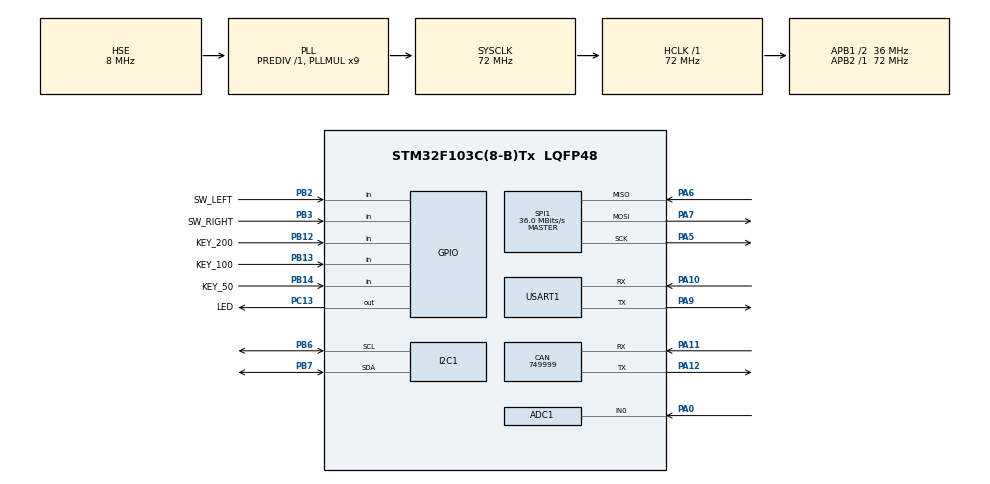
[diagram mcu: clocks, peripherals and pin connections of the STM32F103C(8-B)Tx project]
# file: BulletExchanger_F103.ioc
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ADC1.Channel-2\#ChannelRegularConversion=ADC_CHANNEL_0
ADC1.NbrOfConversionFlag=1
ADC1.Rank-2\#ChannelRegularConversion=1
ADC1.SamplingTime-2\#ChannelRegularConversion=ADC_SAMPLETIME_1CYCLE_5
ADC1.master=1
CAN.CalculateBaudRate=749999
CAN.CalculateTimeBit=1333
CAN.CalculateTimeQuantum=444.44444444444446
Dma.Request0=USART1_TX
Dma.Request1=USART1_RX
Dma.USART1_RX.1.Direction=DMA_PERIPH_TO_MEMORY
Dma.USART1_RX.1.Instance=DMA1_Channel5
Dma.USART1_RX.1.MemDataAlignment=DMA_MDATAALIGN_BYTE
Dma.USART1_RX.1.MemInc=DMA_MINC_ENABLE
Dma.USART1_RX.1.Mode=DMA_NORMAL
Dma.USART1_RX.1.PeriphDataAlignment=DMA_PDATAALIGN_BYTE
Dma.USART1_RX.1.PeriphInc=DMA_PINC_DISABLE
Dma.USART1_RX.1.Priority=DMA_PRIORITY_LOW
Dma.USART1_TX.0.Direction=DMA_MEMORY_TO_PERIPH
Dma.USART1_TX.0.Instance=DMA1_Channel4
Dma.USART1_TX.0.MemDataAlignment=DMA_MDATAALIGN_BYTE
Dma.USART1_TX.0.MemInc=DMA_MINC_ENABLE
Dma.USART1_TX.0.Mode=DMA_NORMAL
Dma.USART1_TX.0.PeriphDataAlignment=DMA_PDATAALIGN_BYTE
Dma.USART1_TX.0.PeriphInc=DMA_PINC_DISABLE
Dma.USART1_TX.0.Priority=DMA_PRIORITY_LOW
FREERTOS.Tasks01=defaultTask,24,256,StartDefaultTask,Default,NULL,Dynamic,NULL,NULL
FREERTOS.configTOTAL_HEAP_SIZE=10240
Mcu.Family=STM32F1
Mcu.Name=STM32F103C(8-B)Tx
Mcu.Package=LQFP48
NVIC.DMA1_Channel4_IRQn=true\:5\:0\:false\:false\:true\:true\:false\:true\:true
NVIC.DMA1_Channel5_IRQn=true\:5\:0\:false\:false\:true\:true\:false\:true\:true
NVIC.PriorityGroup=NVIC_PRIORITYGROUP_4
NVIC.USART1_IRQn=true\:5\:0\:false\:false\:true\:true\:false\:true\:true
PA0-WKUP.Signal=ADCx_IN0
PA10.Mode=Asynchronous
PA10.Signal=USART1_RX
PA11.Mode=CAN_Activate
PA11.Signal=CAN_RX
PA12.Mode=CAN_Activate
PA12.Signal=CAN_TX
PA13.Mode=Serial_Wire
PA13.Signal=SYS_JTMS-SWDIO
PA14.Mode=Serial_Wire
PA14.Signal=SYS_JTCK-SWCLK
PA5.Mode=Full_Duplex_Master
PA5.Signal=SPI1_SCK
PA6.Mode=Full_Duplex_Master
PA6.Signal=SPI1_MISO
PA7.Mode=Full_Duplex_Master
PA7.Signal=SPI1_MOSI
PA9.Mode=Asynchronous
PA9.Signal=USART1_TX
PB12.GPIO_Label=KEY_200
PB12.GPIO_PuPd=GPIO_PULLUP
PB12.Signal=GPIO_Input
PB13.GPIO_Label=KEY_100
PB13.GPIO_PuPd=GPIO_PULLUP
PB13.Signal=GPIO_Input
PB14.GPIO_Label=KEY_50
PB14.GPIO_PuPd=GPIO_PULLUP
PB14.Signal=GPIO_Input
PB2.GPIO_Label=SW_LEFT
PB2.GPIO_PuPd=GPIO_PULLUP
PB2.Signal=GPIO_Input
PB3.GPIO_Label=SW_RIGHT
PB3.GPIO_PuPd=GPIO_PULLUP
PB3.Signal=GPIO_Input
PB6.Mode=I2C
PB6.Signal=I2C1_SCL
PB7.Mode=I2C
PB7.Signal=I2C1_SDA
PC13-TAMPER-RTC.GPIO_Label=LED
PC13-TAMPER-RTC.PinState=GPIO_PIN_SET
PC13-TAMPER-RTC.Signal=GPIO_Output
PD0-OSC_IN.Mode=HSE-External-Oscillator
PD0-OSC_IN.Signal=RCC_OSC_IN
PD1-OSC_OUT.Mode=HSE-External-Oscillator
PD1-OSC_OUT.Signal=RCC_OSC_OUT
ProjectManager.HeapSize=0x200
ProjectManager.StackSize=0x400
ProjectManager.TargetToolchain=Makefile
RCC.AHBFreq_Value=72000000
RCC.APB1CLKDivider=RCC_HCLK_DIV2
RCC.APB1Freq_Value=36000000
RCC.APB1TimFreq_Value=72000000
RCC.APB2Freq_Value=72000000
RCC.APB2TimFreq_Value=72000000
RCC.HCLKFreq_Value=72000000
RCC.PLLMUL=RCC_PLL_MUL9
RCC.PLLSourceVirtual=RCC_PLLSOURCE_HSE
RCC.SYSCLKFreq_VALUE=72000000
RCC.SYSCLKSource=RCC_SYSCLKSOURCE_PLLCLK
RCC.USBFreq_Value=72000000
SH.ADCx_IN0.0=ADC1_IN0,IN0
SPI1.BaudRatePrescaler=SPI_BAUDRATEPRESCALER_2
SPI1.CalculateBaudRate=36.0 MBits/s
SPI1.Direction=SPI_DIRECTION_2LINES
SPI1.Mode=SPI_MODE_MASTER
SPI1.VirtualType=VM_MASTER
USART1.VirtualMode=VM_ASYNC
VP_CRC_VS_CRC.Mode=CRC_Activate
VP_FREERTOS_VS_CMSIS_V2.Mode=CMSIS_V2
VP_RTC_VS_RTC_Activate.Mode=RTC_Enabled
VP_RTC_VS_RTC_Calendar.Mode=RTC_Calendar
VP_TIM3_VS_ClockSourceINT.Mode=Internal
board=custom

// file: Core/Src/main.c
/* USER CODE BEGIN Header */
/**
  ******************************************************************************
  * @file           : main.c
  * @brief          : Main program body
  ******************************************************************************
  * @attention
  *
  * Copyright (c) 2026 STMicroelectronics.
  * All rights reserved.
  *
  * This software is licensed under terms that can be found in the LICENSE file
  * in the root directory of this software component.
  * If no LICENSE file comes with this software, it is provided AS-IS.
  *
  ******************************************************************************
  */
/* USER CODE END Header */
#include "main.h"
#include "cmsis_os.h"
#include "adc.h"
#include "can.h"
#include "crc.h"
#include "dma.h"
#include "i2c.h"
#include "rtc.h"
#include "spi.h"
#include "tim.h"
#include "usart.h"
#include "gpio.h"

void SystemClock_Config(void);
void MX_FREERTOS_Init(void);

int main(void)
{

  /* MCU Configuration--------------------------------------------------------*/

  /* Reset of all peripherals, Initializes the Flash interface and the Systick. */
  HAL_Init();

  /* Configure the system clock */
  SystemClock_Config();

  /* Initialize all configured peripherals */
  MX_GPIO_Init();
  MX_DMA_Init();
  MX_USART1_UART_Init();
  MX_ADC1_Init();
  MX_CAN_Init();
  MX_CRC_Init();
  MX_I2C1_Init();
  MX_RTC_Init();
  MX_SPI1_Init();
  MX_TIM3_Init();

  /* Init scheduler */
  osKernelInitialize();  /* Call init function for freertos objects (in cmsis_os2.c) */
  MX_FREERTOS_Init();

  /* Start scheduler */
  osKernelStart();

  /* We should never get here as control is now taken by the scheduler */

  /* Infinite loop */
  while (1)
  {

  }
}

void SystemClock_Config(void)
{
  RCC_OscInitTypeDef RCC_OscInitStruct = {0};
  RCC_ClkInitTypeDef RCC_ClkInitStruct = {0};
  RCC_PeriphCLKInitTypeDef PeriphClkInit = {0};

  /** Initializes the RCC Oscillators according to the specified parameters
  * in the RCC_OscInitTypeDef structure.
  */
  RCC_OscInitStruct.OscillatorType = RCC_OSCILLATORTYPE_LSI|RCC_OSCILLATORTYPE_HSE;
  RCC_OscInitStruct.HSEState = RCC_HSE_ON;
  RCC_OscInitStruct.HSEPredivValue = RCC_HSE_PREDIV_DIV1;
  RCC_OscInitStruct.HSIState = RCC_HSI_ON;
  RCC_OscInitStruct.LSIState = RCC_LSI_ON;
  RCC_OscInitStruct.PLL.PLLState = RCC_PLL_ON;
  RCC_OscInitStruct.PLL.PLLSource = RCC_PLLSOURCE_HSE;
  RCC_OscInitStruct.PLL.PLLMUL = RCC_PLL_MUL9;
  if (HAL_RCC_OscConfig(&RCC_OscInitStruct) != HAL_OK)
  {
    Error_Handler();
  }

  /** Initializes the CPU, AHB and APB buses clocks
  */
  RCC_ClkInitStruct.ClockType = RCC_CLOCKTYPE_HCLK|RCC_CLOCKTYPE_SYSCLK
                              |RCC_CLOCKTYPE_PCLK1|RCC_CLOCKTYPE_PCLK2;
  RCC_ClkInitStruct.SYSCLKSource = RCC_SYSCLKSOURCE_PLLCLK;
  RCC_ClkInitStruct.AHBCLKDivider = RCC_SYSCLK_DIV1;
  RCC_ClkInitStruct.APB1CLKDivider = RCC_HCLK_DIV2;
  RCC_ClkInitStruct.APB2CLKDivider = RCC_HCLK_DIV1;

  if (HAL_RCC_ClockConfig(&RCC_ClkInitStruct, FLASH_LATENCY_2) != HAL_OK)
  {
    Error_Handler();
  }
  PeriphClkInit.PeriphClockSelection = RCC_PERIPHCLK_RTC|RCC_PERIPHCLK_ADC;
  PeriphClkInit.RTCClockSelection = RCC_RTCCLKSOURCE_LSI;
  PeriphClkInit.AdcClockSelection = RCC_ADCPCLK2_DIV2;
  if (HAL_RCCEx_PeriphCLKConfig(&PeriphClkInit) != HAL_OK)
  {
    Error_Handler();
  }
}

void Error_Handler(void)
{
  __disable_irq();
  while (1)
  {
  }
}

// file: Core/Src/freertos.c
/* USER CODE BEGIN Header */
/**
  ******************************************************************************
  * File Name          : freertos.c
  * Description        : Code for freertos applications
  ******************************************************************************
  * @attention
  *
  * Copyright (c) 2026 STMicroelectronics.
  * All rights reserved.
  *
  * This software is licensed under terms that can be found in the LICENSE file
  * in the root directory of this software component.
  * If no LICENSE file comes with this software, it is provided AS-IS.
  *
  ******************************************************************************
  */
/* USER CODE END Header */

#include "FreeRTOS.h"
#include "task.h"
#include "main.h"
#include "cmsis_os.h"

/* Definitions for defaultTask */
osThreadId_t defaultTaskHandle;
const osThreadAttr_t defaultTask_attributes = {
  .name = "defaultTask",
  .stack_size = 256 * 4,
  .priority = (osPriority_t) osPriorityNormal,
};

/* USER CODE BEGIN FunctionPrototypes */
/* Overridden by programs/BulletExchanger in the repository CMake build. */
__weak void RM_RTOS_Init(void) {}
__weak void RM_RTOS_Threads_Init(void) {}
__weak void RM_RTOS_Default_Task(const void *argument) { UNUSED(argument); }

/* USER CODE END FunctionPrototypes */

void StartDefaultTask(void *argument);

void MX_FREERTOS_Init(void); /* (MISRA C 2004 rule 8.1) */

void MX_FREERTOS_Init(void) {
  /* USER CODE BEGIN Init */
  RM_RTOS_Init();

  /* USER CODE END Init */

  /* Create the thread(s) */
  /* creation of defaultTask */
  defaultTaskHandle = osThreadNew(StartDefaultTask, NULL, &defaultTask_attributes);

  /* USER CODE BEGIN RTOS_THREADS */
  if (defaultTaskHandle == NULL) { Error_Handler(); }
  RM_RTOS_Threads_Init();
  /* add threads, ... */
  /* USER CODE END RTOS_THREADS */

}

void StartDefaultTask(void *argument)
{
  /* USER CODE BEGIN StartDefaultTask */
  RM_RTOS_Default_Task(argument);
  /* Infinite loop */
  for(;;)
  {
    osDelay(1);
  }
  /* USER CODE END StartDefaultTask */
}

/* USER CODE BEGIN Application */
void vApplicationMallocFailedHook(void)
{
  Error_Handler();
}

void vApplicationStackOverflowHook(TaskHandle_t task, char *name)
{
  UNUSED(task);
  UNUSED(name);
  Error_Handler();
}

/* USER CODE END Application */
